AUTOSAR XML (schema 4-0-3)
standard types defined: UInt8
package /AUTOSAR_Platform/DataConstrs
  range DC_UInt8: raw 0..255
package /PATAC/MSM/ComponentTypes
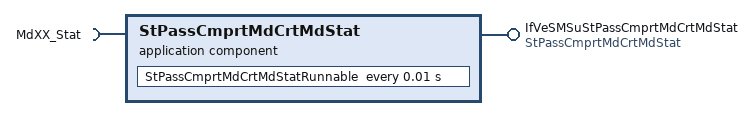
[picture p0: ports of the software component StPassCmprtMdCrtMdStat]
  application sw component type StPassCmprtMdCrtMdStat
    provide port IfVeSMSuStPassCmprtMdCrtMdStat: nonqueued-sender-com-spec{data-element=Val, init-value=0}, provided-interface=StPassCmprtMdCrtMdStat
    require port MdXX_Stat: required-interface=MdXX_Stat
      required-com-specs:
        data-element=Md1_Stat, filter=data-filter-type=ALWAYS, init-value=0
        data-element=Md{10..19}_Stat, filter=data-filter-type=ALWAYS, init-value=0
        data-element=Md2_Stat, filter=data-filter-type=ALWAYS, init-value=0
        data-element=Md{20..29}_Stat, filter=data-filter-type=ALWAYS, init-value=0
        data-element=Md3_Stat, filter=data-filter-type=ALWAYS, init-value=0
        data-element=Md{30..32}_Stat, filter=data-filter-type=ALWAYS, init-value=0
        data-element=Md{4..9}_Stat, filter=data-filter-type=ALWAYS, init-value=0
    behavior StPassCmprtMdCrtMdStat_InternalBehavior
      timing event TMT_StPassCmprtMdCrtMdStatRunnable: start-on-event=StPassCmprtMdCrtMdStatRunnable, period=0.01
      runnable StPassCmprtMdCrtMdStatRunnable
        data-receive-point-by-arguments:
          32 x access:
            REC_MdXX_Stat_Md1_Stat: accessed-variable=MdXX_Stat.Md1_Stat
            REC_MdXX_Stat_Md{10..19}_Stat: accessed-variable=MdXX_Stat.Md{10..19}_Stat
            REC_MdXX_Stat_Md2_Stat: accessed-variable=MdXX_Stat.Md2_Stat
            REC_MdXX_Stat_Md{20..29}_Stat: accessed-variable=MdXX_Stat.Md{20..29}_Stat
            REC_MdXX_Stat_Md3_Stat: accessed-variable=MdXX_Stat.Md3_Stat
            REC_MdXX_Stat_Md{30..32}_Stat: accessed-variable=MdXX_Stat.Md{30..32}_Stat
            REC_MdXX_Stat_Md{4..9}_Stat: accessed-variable=MdXX_Stat.Md{4..9}_Stat
        data-send-points:
          access SEND_StPassCmprtMdCrtMdStat_Val: accessed-variable=IfVeSMSuStPassCmprtMdCrtMdStat.Val
  swc implementation StPassCmprtMdCrtMdStat_Implementation: behavior=StPassCmprtMdCrtMdStat_InternalBehavior
    code-descriptors:
      code Default: artifact-descriptors=autosar-engineering-object={short-label=Default, category=SWSRC}
package /PATAC/MSM/ModeAdjust/PortInterface
  sender receiver interface MdXX_Stat
    32 x data, all with type=UInt8:
      Md1_Stat
      Md{10..19}_Stat
      Md2_Stat
      Md{20..29}_Stat
      Md3_Stat
      Md{30..32}_Stat
      Md{4..9}_Stat
    invalidation-policys:
      data-element=Md{1..3}_Stat, handle-invalid=DONT-INVALIDATE
      data-element=Md5_Stat, handle-invalid=DONT-INVALIDATE
      data-element=Md4_Stat, handle-invalid=DONT-INVALIDATE
      data-element=Md12_Stat, handle-invalid=DONT-INVALIDATE
      data-element=Md6_Stat, handle-invalid=DONT-INVALIDATE
      data-element=Md15_Stat, handle-invalid=DONT-INVALIDATE
      data-element=Md7_Stat, handle-invalid=DONT-INVALIDATE
      data-element=Md13_Stat, handle-invalid=DONT-INVALIDATE
      data-element=Md8_Stat, handle-invalid=DONT-INVALIDATE
      data-element=Md18_Stat, handle-invalid=DONT-INVALIDATE
      data-element=Md9_Stat, handle-invalid=DONT-INVALIDATE
      data-element=Md14_Stat, handle-invalid=DONT-INVALIDATE
      data-element=Md10_Stat, handle-invalid=DONT-INVALIDATE
      data-element=Md16_Stat, handle-invalid=DONT-INVALIDATE
      data-element=Md11_Stat, handle-invalid=DONT-INVALIDATE
      data-element=Md20_Stat, handle-invalid=DONT-INVALIDATE
      data-element=Md17_Stat, handle-invalid=DONT-INVALIDATE
      data-element=Md19_Stat, handle-invalid=DONT-INVALIDATE
      data-element=Md22_Stat, handle-invalid=DONT-INVALIDATE
      data-element=Md21_Stat, handle-invalid=DONT-INVALIDATE
      data-element=Md24_Stat, handle-invalid=DONT-INVALIDATE
      data-element=Md23_Stat, handle-invalid=DONT-INVALIDATE
      data-element=Md26_Stat, handle-invalid=DONT-INVALIDATE
      data-element=Md25_Stat, handle-invalid=DONT-INVALIDATE
      data-element=Md28_Stat, handle-invalid=DONT-INVALIDATE
      data-element=Md27_Stat, handle-invalid=DONT-INVALIDATE
      data-element=Md30_Stat, handle-invalid=DONT-INVALIDATE
      data-element=Md29_Stat, handle-invalid=DONT-INVALIDATE
      data-element=Md32_Stat, handle-invalid=DONT-INVALIDATE
      data-element=Md31_Stat, handle-invalid=DONT-INVALIDATE
  sender receiver interface StPassCmprtMdCrtMdStat: invalidation-policy{data-element=Val, handle-invalid=DONT-INVALIDATE}
    data Val: type=UInt8
